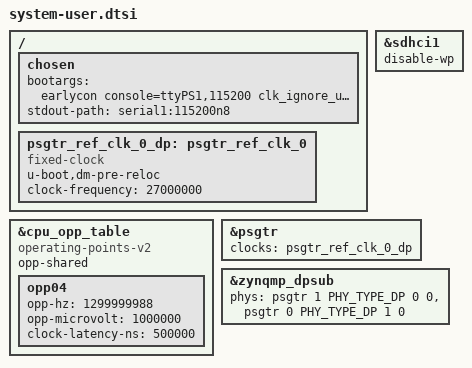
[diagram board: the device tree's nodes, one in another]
/include/ "system-conf.dtsi"
/ 

{
	chosen {
                bootargs = "earlycon console=ttyPS1,115200 clk_ignore_unused root=/dev/mmcblk1p2 rw rootwait cma=1000M";
                stdout-path = "serial1:115200n8";
        };

	psgtr_ref_clk_0_dp: psgtr_ref_clk_0 {
	        u-boot,dm-pre-reloc;
	        compatible = "fixed-clock";
	        #clock-cells = <0>;
	        clock-frequency = <27000000>;
	    };
};

&cpu_opp_table {
		compatible = "operating-points-v2";
		opp-shared;
		opp04 {
			opp-hz = /bits/ 64 <1299999988>;
			opp-microvolt = <1000000>;
			clock-latency-ns = <500000>;
			};
};



&sdhci1 {
    disable-wp;
};


&psgtr {
    status = "okay";
    clocks = <&psgtr_ref_clk_0_dp>;
    clock-names = "ref0";
};

&zynqmp_dpsub {
    status = "okay";

    phys = <&psgtr 1 PHY_TYPE_DP 0 0>, <&psgtr 0 PHY_TYPE_DP 1 0>;
    phy-names = "dp-phy0", "dp-phy1";
};
